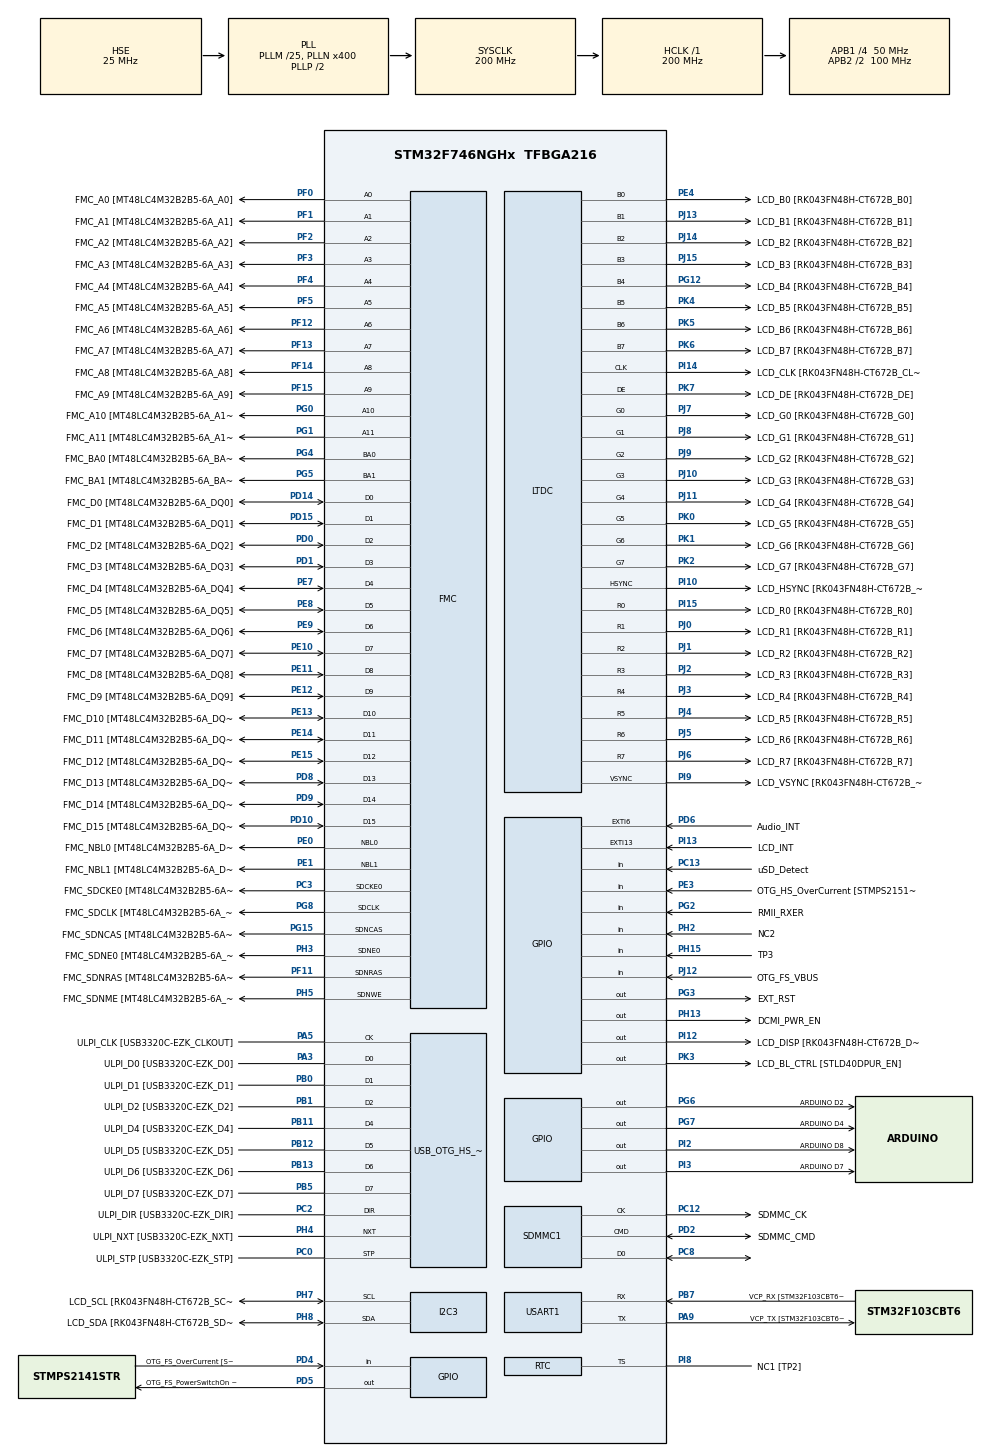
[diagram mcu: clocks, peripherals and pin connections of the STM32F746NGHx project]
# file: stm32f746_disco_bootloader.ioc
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PD12.GPIO_Label=QSPI_D1 [N25Q128A13EF840E_DQ1]
FMC.SDClockPeriod2=FMC_SDRAM_CLOCK_PERIOD_2
FATFS._USE_LFN=1
FMC.SDClockPeriod1=FMC_SDRAM_CLOCK_PERIOD_2
SH.FMC_A0.0=FMC_A0,12b-sda1
FATFS0.BSP.api=Unknown
PH15.GPIO_Label=TP3
NVIC.TIM6_DAC_IRQn=true\:0\:0\:false\:false\:true\:false\:true
PG8.Signal=FMC_SDCLK
PG0.Signal=FMC_A10
PI15.GPIO_Label=LCD_R0 [RK043FN48H-CT672B_R0]
PK1.Signal=LTDC_G6
SH.FMC_D5_DA5.0=FMC_D5,sd-16b-d1
PF10.GPIO_PuPd=GPIO_NOPULL
SH.FMC_D9_DA9.0=FMC_D9,sd-16b-d1
PG15.GPIO_Label=FMC_SDNCAS [MT48LC4M32B2B5-6A_CAS]
PF7.Signal=ADC3_IN5
NVIC.DMA2D_IRQn=true\:0\:0\:false\:false\:true\:true\:true
RCC.PLL48CLockSelection=RCC_CLK48SOURCE_PLLSAIP
SH.FMC_SDNWE.0=FMC_SDNWE,12b-sda1
PH9.Signal=DCMI_D0
SH.FMC_D11_DA11.0=FMC_D11,sd-16b-d1
PJ5.Mode=RGB888
RCC.APB2TimFreq_Value=200000000
PB6.Signal=QUADSPI_BK1_NCS
PC7.Signal=USART6_RX
PD0.Signal=FMC_D2_DA2
PD8.Signal=FMC_D13_DA13
PE1.Signal=FMC_NBL1
FATFS0.BSP.ip=GPIO
NVIC.TIM1_TRG_COM_TIM11_IRQn=true\:0\:0\:false\:false\:true\:true\:true
PF1.GPIO_Label=FMC_A1 [MT48LC4M32B2B5-6A_A1]
PI4.GPIO_Label=SAI2_MCLKA [WM8994ECS/R_MCLK1]
PK4.GPIO_Label=LCD_B5 [RK043FN48H-CT672B_B5]
PD1.GPIO_Label=FMC_D3 [MT48LC4M32B2B5-6A_DQ3]
PB12.GPIO_Label=ULPI_D5 [USB3320C-EZK_D5]
PJ14.Mode=RGB888
FMC.SelfRefreshTime1=4
PF12.GPIO_Label=FMC_A6 [MT48LC4M32B2B5-6A_A6]
LTDC.PixelFormat_L0=LTDC_PIXEL_FORMAT_RGB565
SH.S_TIM12_CH1.0=TIM12_CH1
PC4.GPIO_Label=RMII_RXD0 [LAN8742A-CZ-TR_RXD0]
PE9.Signal=FMC_D6_DA6
SH.FMC_A2.0=FMC_A2,12b-sda1
PB1.GPIO_Label=ULPI_D2 [USB3320C-EZK_D2]
PE4.GPIO_Label=LCD_B0 [RK043FN48H-CT672B_B0]
PG4.GPIO_Label=FMC_BA0 [MT48LC4M32B2B5-6A_BA0]
PA8.Signal=S_TIM1_CH1
SH.FMC_D1_DA1.0=FMC_D1,sd-16b-d1
LTDC.HSync=41
PJ14.Signal=LTDC_B2
PB9.Signal=I2C1_SDA
Mcu.Package=TFBGA216
PB1.Signal=USB_OTG_HS_ULPI_D2
PB14.GPIO_PuPd=GPIO_NOPULL
NVIC.TimeBase=TIM6_DAC_IRQn
PD12.Signal=QUADSPI_BK1_IO1
NVIC.TimeBaseIP=TIM6
PB9.GPIO_PuPd=GPIO_NOPULL
PA10.Signal=USB_OTG_FS_ID
VP_RTC_VS_RTC_Calendar.Mode=RTC_Calendar
PE12.GPIO_Label=FMC_D9 [MT48LC4M32B2B5-6A_DQ9]
FMC.WriteRecoveryTime1=3
RCC.APB2CLKDivider=RCC_HCLK_DIV2
LTDC.VSync=10
RCC.APB1TimFreq_Value=100000000
PC14/OSC32_IN.GPIO_Label=RCC_OSC32_IN
FMC.RowCycleDelay2=7
FMC.RowCycleDelay1=7
PB13.Mode=Host_HS
PJ13.Mode=RGB888
PH8.Mode=I2C
PF9.GPIO_PuPd=GPIO_NOPULL
PA4.GPIO_Label=DCMI_HSYNC
PA8.GPIO_Speed=GPIO_SPEED_FREQ_LOW
PD15.Signal=FMC_D1_DA1
PJ1.GPIO_Label=LCD_R2 [RK043FN48H-CT672B_R2]
PG12.Signal=LTDC_B4
PA5.Mode=Host_HS
FATFS0.BSP.STBoard=false
PK4.Signal=LTDC_B5
SH.FMC_A4.0=FMC_A4,12b-sda1
PH13.Signal=GPIO_Output
PI13.GPIO_ModeDefaultEXTI=GPIO_MODE_EVT_RISING
PG5.Signal=FMC_A15_BA1
PC13.Signal=GPIO_Input
SH.FMC_D10_DA10.0=FMC_D10,sd-16b-d1
FATFS0.BSP.mode=Input
PD3.Signal=DCMI_D5
PI10.Mode=RGB888
PC2.Signal=USB_OTG_HS_ULPI_DIR
PI12.Signal=GPIO_Output
TIM11.Prescaler=4999
PJ11.Signal=LTDC_G4
RCC.PLLSAIRDiv=RCC_PLLSAIDIVR_4
PF8.GPIO_Label=ARDUINO A3
LTDC.ImageWidth_L0=480
PD10.Signal=FMC_D15_DA15
PJ6.Mode=RGB888
PA3.Mode=Host_HS
PB8.GPIO_Label=ARDUINO SCL/D15
PJ8.GPIO_Label=LCD_G1 [RK043FN48H-CT672B_G1]
PJ3.Signal=LTDC_R4
PI8.GPIO_Label=NC1 [TP2]
PA8.GPIO_Label=ARDUINO PWM/D10
Dma.USART1_RX.0.Direction=DMA_PERIPH_TO_MEMORY
PE8.GPIO_Label=FMC_D5 [MT48LC4M32B2B5-6A_DQ5]
PH11.GPIO_Label=DCMI_D2
PJ11.GPIO_Label=LCD_G4 [RK043FN48H-CT672B_G4]
PB14.Signal=SPI2_MISO
PA5.Signal=USB_OTG_HS_ULPI_CK
PC12.Mode=SD_1_bit
PF10.GPIO_Mode=GPIO_MODE_ANALOG
PJ4.GPIO_Label=LCD_R5 [RK043FN48H-CT672B_R5]
PE1.GPIO_Label=FMC_NBL1 [MT48LC4M32B2B5-6A_DQM1]
PK7.GPIO_Label=LCD_DE [RK043FN48H-CT672B_DE]
PI7.Signal=SAI2_FS_A
FMC.ReadBurst1=FMC_SDRAM_RBURST_ENABLE
SH.FMC_A6.0=FMC_A6,12b-sda1
FMC.ReadBurst2=FMC_SDRAM_RBURST_ENABLE
PE14.Signal=FMC_D11_DA11
PB4.GPIO_Label=ARDUINO PWM/D3
PB15.GPIO_Label=ARDUINO MOSI/PWM/D11
PG7.GPIO_Label=ARDUINO D4
PI2.Signal=GPIO_Output
PF4.GPIO_Label=FMC_A4 [MT48LC4M32B2B5-6A_A4]
PA1.GPIO_Label=RMII_REF_CLK [LAN8742A-CZ-TR_REFCLK0]
PF13.Signal=FMC_A7
PA0/WKUP.GPIO_PuPd=GPIO_NOPULL
PJ15.GPIO_Label=LCD_B3 [RK043FN48H-CT672B_B3]
PC7.GPIO_Label=ARDUINO RX/D0
PC8.Mode=SD_1_bit
PJ15.Mode=RGB888
PA5.GPIO_Label=ULPI_CLK [USB3320C-EZK_CLKOUT]
PK4.Mode=RGB888
PC12.GPIO_Label=SDMMC_CK
PE5.GPIO_Label=DCMI_D6
PJ8.Signal=LTDC_G1
PJ0.GPIO_Label=LCD_R1 [RK043FN48H-CT672B_R1]
ProjectManager.HeapSize=0xF000
PB1.Mode=Host_HS
PH6.Signal=S_TIM12_CH1
NVIC.PriorityGroup=NVIC_PRIORITYGROUP_4
PF0.GPIO_Label=FMC_A0 [MT48LC4M32B2B5-6A_A0]
PI1.GPIO_Mode=GPIO_MODE_AF_PP
PE3.Signal=GPIO_Input
PJ4.Mode=RGB888
PC15/OSC32_OUT.Signal=RCC_OSC32_OUT
PF4.Signal=FMC_A4
PD2.Signal=SDMMC1_CMD
FATFS0.BSP.name=Detect_SDIO
PI1.GPIO_Label=ARDUINO SCK/D13
Mcu.Family=STM32F7
LTDC.BlendingFactor1_L0=LTDC_BLENDING_FACTOR1_PAxCA
PK3.Signal=GPIO_Output
SH.FMC_A8.0=FMC_A8,12b-sda1
PC15/OSC32_OUT.GPIO_Label=RCC_OSC32_OUT
PH14.Signal=DCMI_D4
PH10.Signal=DCMI_D1
SH.FMC_D14_DA14.0=FMC_D14,sd-16b-d1
PG2.Signal=GPIO_Input
PE11.GPIO_Label=FMC_D8 [MT48LC4M32B2B5-6A_DQ8]
PD0.GPIO_Label=FMC_D2 [MT48LC4M32B2B5-6A_DQ2]
PC14/OSC32_IN.Mode=LSE-External-Oscillator
SH.FMC_A14_BA0.0=FMC_BA0,FourSdramBanks1
SH.FMC_A11.0=FMC_A11,12b-sda1
PB13.GPIO_Label=ULPI_D6 [USB3320C-EZK_D6]
PG5.GPIO_Label=FMC_BA1 [MT48LC4M32B2B5-6A_BA1]
PB15.Signal=SPI2_MOSI
VP_RTC_VS_RTC_Alarm_B_Intern.Mode=Alarm B
PG15.Signal=FMC_SDNCAS
PG11.Signal=ETH_TX_EN
PJ5.GPIO_Label=LCD_R6 [RK043FN48H-CT672B_R6]
PJ14.GPIO_Label=LCD_B2 [RK043FN48H-CT672B_B2]
PD13.Signal=QUADSPI_BK1_IO3
PA15.GPIO_Label=ARDUINO PWM/D9
PJ2.Signal=LTDC_R3
SH.FMC_NBL1.0=FMC_NBL1,Sd2ByteEnable1
LTDC.WindowX1_L0=480
PI9.Mode=RGB888
PK2.Mode=RGB888
PA15.GPIO_ModeDefaultPP=GPIO_MODE_AF_PP
Dma.USART1_RX.0.Priority=DMA_PRIORITY_LOW
PA9.GPIO_Mode=GPIO_MODE_AF_PP
RCC.HSE_VALUE=25000000
FMC.ExitSelfRefreshDelay1=7
PF7.GPIO_Mode=GPIO_MODE_ANALOG
PI14.Mode=RGB888
PF8.GPIO_PuPd=GPIO_NOPULL
PA14.Mode=Serial_Wire
PH7.GPIO_Label=LCD_SCL [RK043FN48H-CT672B_SCL]
PJ7.GPIO_Label=LCD_G0 [RK043FN48H-CT672B_G0]
PF11.Signal=FMC_SDNRAS
PB5.Mode=Host_HS
PC11.GPIO_Label=SDMMC_D3
PJ12.GPIO_Label=OTG_FS_VBUS
PB7.Signal=USART1_RX
SH.S_TIM3_CH1.0=TIM3_CH1
Dma.USART1_RX.0.MemInc=DMA_MINC_ENABLE
PI8.Mode=Timestamp enabled - Input Enabled to TS
PB7.GPIO_Label=VCP_RX [STM32F103CBT6_PA2]
PD13.GPIO_Label=QSPI_D3 [N25Q128A13EF840E_DQ3]
PA6.Signal=DCMI_PIXCLK
PB12.Mode=Host_HS
PB15.GPIO_PuPd=GPIO_NOPULL
PD5.GPIO_Label=OTG_FS_PowerSwitchOn [STMPS2141STR_EN]
PA15.Signal=S_TIM2_CH1_ETR
PF8.Signal=ADC3_IN6
PG0.GPIO_Label=FMC_A10 [MT48LC4M32B2B5-6A_A10]
PI0.GPIO_Label=ARDUINO PWM/CS/D5
PA0/WKUP.GPIO_Mode=GPIO_MODE_ANALOG
Dma.USART1_RX.0.FIFOMode=DMA_FIFOMODE_DISABLE
FATFS._FS_LOCK=0
I2C3.Timing=0x00C0EAFF
PB5.GPIO_Label=ULPI_D7 [USB3320C-EZK_D7]
PG11.GPIO_Label=RMII_TX_EN [LAN8742A-CZ-TR_TXEN]
PD3.GPIO_Label=DCMI_D5
PC5.Signal=ETH_RXD1
PE7.Signal=FMC_D4_DA4
PD6.Signal=GPXTI6
Dma.Request0=USART1_RX
PF3.GPIO_Label=FMC_A3 [MT48LC4M32B2B5-6A_A3]
PI15.Mode=RGB888
PE2.GPIO_Label=QSPI_D2 [N25Q128A13EF840E_DQ2]
Dma.USART1_RX.0.Instance=DMA2_Stream2
PB4.Signal=S_TIM3_CH1
PG2.GPIO_Label=RMII_RXER
PA3.Signal=USB_OTG_HS_ULPI_D0
PK1.Mode=RGB888
PK6.Signal=LTDC_B7
NVIC.LTDC_IRQn=true\:0\:0\:false\:false\:true\:true\:true
PD15.GPIO_Label=FMC_D1 [MT48LC4M32B2B5-6A_DQ1]
LTDC.WindowY1_L0=272
PG7.Signal=GPIO_Output
PJ8.Mode=RGB888
PH12.GPIO_Label=DCMI_D3
PC11.Signal=SDMMC1_D3
PI14.Signal=LTDC_CLK
PC8.Signal=SDMMC1_D0
PC2.Mode=Host_HS
PE14.GPIO_Label=FMC_D11 [MT48LC4M32B2B5-6A_DQ11]
PD9.Signal=FMC_D14_DA14
PA9.GPIO_PuPd=GPIO_NOPULL
PA12.GPIO_Label=OTG_FS_P
PD8.GPIO_Label=FMC_D13 [MT48LC4M32B2B5-6A_DQ13]
FATFS0.BSP.instance=PC13
PG8.GPIO_Label=FMC_SDCLK [MT48LC4M32B2B5-6A_CLK]
USART1.VirtualMode-Asynchronous=VM_ASYNC
PA13.Signal=SYS_JTMS-SWDIO
PA9.Mode=Asynchronous
SH.S_TIM1_CH1.0=TIM1_CH1
PF6.Signal=ADC3_IN4
PB10.GPIO_Label=ULPI_D3 [USB3320C-EZK_D3]
SH.FMC_D13_DA13.0=FMC_D13,sd-16b-d1
PH8.Signal=I2C3_SDA
RCC.USBFreq_Value=48000000
PF9.GPIO_Label=ARDUINO A2
PD10.GPIO_Label=FMC_D15 [MT48LC4M32B2B5-6A_DQ15]
PA1.Signal=ETH_REF_CLK
PD2.Mode=SD_1_bit
PK5.Mode=RGB888
board=STM32F746G-DISCO
PG12.Mode=RGB888
RCC.VCOOutputFreq_Value=400000000
PI9.Signal=LTDC_VSYNC
PH4.GPIO_Label=ULPI_NXT [USB3320C-EZK_NXT]
PI13.GPIO_Label=LCD_INT
PI4.Signal=SAI2_MCLK_A
PC1.GPIO_Label=RMII_MDC [LAN8742A-CZ-TR_MDC]
SH.FMC_D12_DA12.0=FMC_D12,sd-16b-d1
PF15.GPIO_Label=FMC_A9 [MT48LC4M32B2B5-6A_A9]
PI1.GPIO_Speed=GPIO_SPEED_FREQ_LOW
PF1.Signal=FMC_A1
PF8.GPIO_Mode=GPIO_MODE_ANALOG
PJ0.Signal=LTDC_R1
PE0.Signal=FMC_NBL0
RTC.Alarm-Alarm\ A=RTC_ALARM_A
PE7.GPIO_Label=FMC_D4 [MT48LC4M32B2B5-6A_DQ4]
PE12.Signal=FMC_D9_DA9
FATFS._MAX_SS=4096
RCC.SYSCLKFreq_VALUE=200000000
PJ5.Signal=LTDC_R6
PA15.GPIO_Speed=GPIO_SPEED_FREQ_LOW
RCC.HSI_VALUE=16000000
PA8.GPIO_PuPd=GPIO_NOPULL
PH0/OSC_IN.GPIO_Label=OSC_25M [NZ2520SB-25.00M_OUT]
PF9.GPIO_Mode=GPIO_MODE_ANALOG
RCC.PLLQ=10
PI3.GPIO_Label=ARDUINO D7
PH3.Signal=FMC_SDNE0
RCC.PLLM=25
RCC.PLLN=400
PA9.GPIO_Speed=GPIO_SPEED_FREQ_LOW
PB8.GPIO_Speed=GPIO_SPEED_FREQ_LOW
PJ2.GPIO_Label=LCD_R3 [RK043FN48H-CT672B_R3]
VP_CRC_VS_CRC.Mode=CRC_Activate
LTDC.ImageHeight_L0=272
PB14.GPIO_Mode=GPIO_MODE_AF_PP
RCC.PLLI2SN=100
PB12.Signal=USB_OTG_HS_ULPI_D5
PJ13.Signal=LTDC_B1
PK1.GPIO_Label=LCD_G6 [RK043FN48H-CT672B_G6]
PA3.GPIO_Label=ULPI_D0 [USB3320C-EZK_D0]
PI12.PinState=GPIO_PIN_SET
SH.FMC_D7_DA7.0=FMC_D7,sd-16b-d1
RTC.Alarm_B-Alarm\ B=RTC_ALARM_B
PK5.Signal=LTDC_B6
PB15.GPIO_Mode=GPIO_MODE_AF_PP
VP_SYS_VS_tim6.Mode=TIM6
PJ9.Mode=RGB888
PH12.Signal=DCMI_D3
FMC.RCDDelay1=2
VP_FATFS_VS_SDIO.Mode=SDIO
PK0.Mode=RGB888
PG4.Signal=FMC_A14_BA0
PC12.Signal=SDMMC1_CK
PB14.GPIO_Label=ARDUINO MISO/D12
PA14.GPIO_Label=SWCLK
PG6.GPIO_Label=ARDUINO D2
PH6.GPIO_Label=ARDUINO PWM/D6
FMC.LoadToActiveDelay1=2
PK6.GPIO_Label=LCD_B7 [RK043FN48H-CT672B_B7]
PC6.GPIO_Label=ARDUINO TX/D1
VP_RTC_VS_RTC_Activate.Mode=RTC_Enabled
PI6.GPIO_Label=SAI2_SDA [WM8994ECS/R_DACDAT1]
PB6.GPIO_Label=QSPI_NCS [N25Q128A13EF840E_S]
PJ6.GPIO_Label=LCD_R7 [RK043FN48H-CT672B_R7]
PB13.Signal=USB_OTG_HS_ULPI_D6
PD6.GPIO_Label=Audio_INT
PG13.Signal=ETH_TXD0
PE6.GPIO_Label=DCMI_D7
PF6.GPIO_Label=ARDUINO A5
RCC.SYSCLKSource=RCC_SYSCLKSOURCE_PLLCLK
PJ10.Signal=LTDC_G3
SH.FMC_A15_BA1.0=FMC_BA1,FourSdramBanks1
PB7.GPIO_Mode=GPIO_MODE_AF_PP
PJ13.GPIO_Label=LCD_B1 [RK043FN48H-CT672B_B1]
PI0.GPIO_PuPd=GPIO_NOPULL
PH5.Signal=FMC_SDNWE
PD4.Signal=GPIO_Input
PH1/OSC_OUT.Signal=RCC_OSC_OUT
PC3.Signal=FMC_SDCKE0
PE5.Signal=DCMI_D6
PF10.GPIO_Label=ARDUINO A1
PH10.GPIO_Label=DCMI_D1
PB2.Signal=QUADSPI_CLK
FATFS0.BSP.i2caddr=0
PK7.Mode=RGB888
PJ2.Mode=RGB888
PI6.Signal=SAI2_SD_A
PI3.Signal=GPIO_Output
PE2.Signal=QUADSPI_BK1_IO2
PF3.Signal=FMC_A3
PE10.Signal=FMC_D7_DA7
FATFS._FS_TIMEOUT=10000
RCC.SDMMCClockSelection=RCC_SDMMC1CLKSOURCE_CLK48
PD6.GPIO_ModeDefaultEXTI=GPIO_MODE_EVT_RISING
FATFS0.BSP.solution=PC13
PJ4.Signal=LTDC_R5
SH.FMC_A1.0=FMC_A1,12b-sda1
PH2.Signal=GPIO_Input
NVIC.DMA2_Stream2_IRQn=true\:0\:0\:false\:false\:true\:false\:true
SH.FMC_SDCLK.0=FMC_SDCLK,12b-sda1
PF14.Signal=FMC_A8
VP_DMA2D_VS_DMA2D.Mode=DMA2D_Activate
PF6.GPIO_Mode=GPIO_MODE_ANALOG
PE10.GPIO_Label=FMC_D7 [MT48LC4M32B2B5-6A_DQ7]
PJ1.Mode=RGB888
SH.FMC_D3_DA3.0=FMC_D3,sd-16b-d1
FATFS._MIN_SS=512
PI10.GPIO_Label=LCD_HSYNC [RK043FN48H-CT672B_HSYNC]
PB7.GPIO_PuPd=GPIO_NOPULL
PK3.PinState=GPIO_PIN_SET
PH15.Signal=GPIO_Input
PD9.GPIO_Label=FMC_D14 [MT48LC4M32B2B5-6A_DQ14]
PG9.Signal=DCMI_VSYNC
PA9.GPIO_Label=VCP_TX [STM32F103CBT6_PA3]
PB8.GPIO_PuPd=GPIO_NOPULL
PC6.Signal=USART6_TX
PB11.GPIO_Label=ULPI_D4 [USB3320C-EZK_D4]
PD7.Signal=SPDIFRX_IN0
PD1.Signal=FMC_D3_DA3
PA11.GPIO_Label=OTG_FS_N
PF14.GPIO_Label=FMC_A8 [MT48LC4M32B2B5-6A_A8]
PC0.Signal=USB_OTG_HS_ULPI_STP
RCC.APB1CLKDivider=RCC_HCLK_DIV4
PF13.GPIO_Label=FMC_A7 [MT48LC4M32B2B5-6A_A7]
PG13.GPIO_Label=RMII_TXD0 [LAN8742A-CZ-TR_TXD0]
PG10.Signal=SAI2_SD_B
SH.FMC_A3.0=FMC_A3,12b-sda1
PJ7.Signal=LTDC_G0
FMC.CASLatency1=FMC_SDRAM_CAS_LATENCY_3
PB11.Mode=Host_HS
PI0.GPIO_Speed=GPIO_SPEED_FREQ_LOW
PB14.GPIO_Speed=GPIO_SPEED_FREQ_LOW
SH.FMC_D15_DA15.0=FMC_D15,sd-16b-d1
PA9.Signal=USART1_TX
PB4.GPIO_PuPd=GPIO_NOPULL
PE9.GPIO_Label=FMC_D6 [MT48LC4M32B2B5-6A_DQ6]
Dma.USART1_RX.0.PeriphInc=DMA_PINC_DISABLE
PB10.Signal=USB_OTG_HS_ULPI_D3
FATFS.BSP.number=1
PJ15.Signal=LTDC_B3
PH9.GPIO_Label=DCMI_D0
PI9.GPIO_Label=LCD_VSYNC [RK043FN48H-CT672B_VSYNC]
PA8.GPIO_ModeDefaultPP=GPIO_MODE_AF_PP
PE15.Signal=FMC_D12_DA12
PE8.Signal=FMC_D5_DA5
PI1.Signal=SPI2_SCK
FATFS0.BSP.i2creg=0
PA0/WKUP.GPIO_Label=ARDUINO A0
PG14.GPIO_Label=RMII_TXD1 [LAN8742A-CZ-TR_TXD1]
PA13.Mode=Serial_Wire
SH.FMC_SDNCAS.0=FMC_SDNCAS,12b-sda1
PH4.Mode=Host_HS
PF7.GPIO_PuPd=GPIO_NOPULL
PH14.GPIO_Label=DCMI_D4
PA4.Signal=DCMI_HSYNC
PB5.Signal=USB_OTG_HS_ULPI_D7
PE13.GPIO_Label=FMC_D10 [MT48LC4M32B2B5-6A_DQ10]
PD11.Signal=QUADSPI_BK1_IO0
SH.FMC_A5.0=FMC_A5,12b-sda1
LTDC.Alpha_L0=255
PA11.Signal=USB_OTG_FS_DM
SH.S_TIM2_CH1_ETR.0=TIM2_CH1
PK3.GPIO_Label=LCD_BL_CTRL [STLD40DPUR_EN]
PF9.Signal=ADC3_IN7
PJ10.Mode=RGB888
PF6.GPIO_PuPd=GPIO_NOPULL
PC3.GPIO_Label=FMC_SDCKE0 [MT48LC4M32B2B5-6A_CKE]
PG3.GPIO_Label=EXT_RST
PB0.Signal=USB_OTG_HS_ULPI_D1
PC1.Signal=ETH_MDC
PG10.GPIO_Label=SAI2_SDB [WM8994ECS/R_ADCDAT1]
PD2.GPIO_Label=SDMMC_CMD
PH2.GPIO_Label=NC2
PC3.Mode=SdramChipSelect1_1
PK7.Signal=LTDC_DE
RCC.CortexFreq_Value=200000000
PG6.Signal=GPIO_Output
LTDC.HBP=13
PC10.Signal=SDMMC1_D2
SH.FMC_NBL0.0=FMC_NBL0,Sd2ByteEnable1
PC0.GPIO_Label=ULPI_STP [USB3320C-EZK_STP]
SH.FMC_D6_DA6.0=FMC_D6,sd-16b-d1
SDMMC1.ClockDiv=4
PA0/WKUP.Signal=ADCx_IN0
PB0.GPIO_Label=ULPI_D1 [USB3320C-EZK_D1]
PH5.GPIO_Label=FMC_SDNME [MT48LC4M32B2B5-6A_WE]
PI5.GPIO_Label=SAI2_SCKA [WM8994ECS/R_BCLK1]
PC13.GPIO_Label=uSD_Detect
PK5.GPIO_Label=LCD_B6 [RK043FN48H-CT672B_B6]
PB11.Signal=USB_OTG_HS_ULPI_D4
PI14.GPIO_Label=LCD_CLK [RK043FN48H-CT672B_CLK]
VP_RTC_VS_RTC_Alarm_A_Intern.Mode=Alarm A
ProjectManager.StackSize=0xF000
PH3.Mode=SdramChipSelect1_1
PJ6.Signal=LTDC_R7
SH.FMC_A7.0=FMC_A7,12b-sda1
PA12.Signal=USB_OTG_FS_DP
PH0/OSC_IN.Mode=HSE-External-Oscillator
PD11.GPIO_Label=QSPI_D0 [N25Q128A13EF840E_DQ0]
RCC.HCLKFreq_Value=200000000
PF11.GPIO_Label=FMC_SDNRAS [MT48LC4M32B2B5-6A_RAS]
PF12.Signal=FMC_A6
PI13.Signal=GPXTI13
SH.FMC_A10.0=FMC_A10,12b-sda1
RCC.AHBFreq_Value=200000000
SH.FMC_D8_DA8.0=FMC_D8,sd-16b-d1
FMC.RPDelay2=2
FMC.RPDelay1=2
PI8.Signal=RTC_TS
SH.FMC_D2_DA2.0=FMC_D2,sd-16b-d1
NVIC.I2C3_EV_IRQn=true\:0\:0\:false\:false\:true\:true\:true
PE13.Signal=FMC_D10_DA10
PF7.GPIO_Label=ARDUINO A4
PI1.GPIO_PuPd=GPIO_NOPULL
PI5.Signal=SAI2_SCK_A
PK6.Mode=RGB888
PI0.Signal=S_TIM5_CH4
PA10.GPIO_Label=OTG_FS_ID
LTDC.HFP=32
LTDC.BlendingFactor2_L0=LTDC_BLENDING_FACTOR2_PAxCA
SH.ADCx_IN0.0=ADC3_IN0
FMC.ReadPipeDelay1=FMC_SDRAM_RPIPE_DELAY_1
FMC.ReadPipeDelay2=FMC_SDRAM_RPIPE_DELAY_1
PE4.Mode=RGB888
SH.FMC_SDNRAS.0=FMC_SDNRAS,12b-sda1
DMA2D.ColorMode=DMA2D_OUTPUT_RGB565
LTDC.ActiveW=480
PE4.Signal=LTDC_B0
PH1/OSC_OUT.Mode=HSE-External-Oscillator
PD7.GPIO_Label=SPDIF_RX0 [74LVC1G04SE_4]
PH7.Mode=I2C
PJ0.Mode=RGB888
PJ9.Signal=LTDC_G2
SH.FMC_D0_DA0.0=FMC_D0,sd-16b-d1
PJ12.Signal=GPIO_Input
PC14/OSC32_IN.Signal=RCC_OSC32_IN
PK0.GPIO_Label=LCD_G5 [RK043FN48H-CT672B_G5]
PA2.GPIO_Label=RMII_MDIO [LAN8742A-CZ-TR_MDIO]
PF5.GPIO_Label=FMC_A5 [MT48LC4M32B2B5-6A_A5]
SH.FMC_A9.0=FMC_A9,12b-sda1
PJ1.Signal=LTDC_R2
SH.FMC_D4_DA4.0=FMC_D4,sd-16b-d1
PI12.GPIO_Label=LCD_DISP [RK043FN48H-CT672B_DISP] 
PE0.GPIO_Label=FMC_NBL0 [MT48LC4M32B2B5-6A_DQM0]
PH3.GPIO_Label=FMC_SDNE0 [MT48LC4M32B2B5-6A_CS]
PF5.Signal=FMC_A5
RCC.PLLSAIP=RCC_PLLSAIP_DIV4
RCC.PLLSAIR=5
PH7.Signal=I2C3_SCL
PB9.GPIO_Speed=GPIO_SPEED_FREQ_LOW
PJ3.GPIO_Label=LCD_R4 [RK043FN48H-CT672B_R4]
PK2.GPIO_Label=LCD_G7 [RK043FN48H-CT672B_G7]
Dma.USART1_RX.0.Mode=DMA_CIRCULAR
PJ7.Mode=RGB888
PF0.Signal=FMC_A0
PI2.GPIO_Label=ARDUINO D8
PC2.GPIO_Label=ULPI_DIR [USB3320C-EZK_DIR]
PB7.GPIO_Speed=GPIO_SPEED_FREQ_LOW
PB3.GPIO_Label=SWO
RCC.PLLSourceVirtual=RCC_PLLSOURCE_HSE
PK2.Signal=LTDC_G7
LTDC.FBStartAdress_L0=0xC0000000
Dma.USART1_RX.0.PeriphDataAlignment=DMA_PDATAALIGN_BYTE
PB9.GPIO_Label=ARDUINO SDA/D14
PC10.GPIO_Label=SDMMC_D2
PH11.Signal=DCMI_D2
PG3.Signal=GPIO_Output
PG1.Signal=FMC_A11
PC4.Signal=ETH_RXD0
PI0.GPIO_ModeDefaultPP=GPIO_MODE_AF_PP
PI10.Signal=LTDC_HSYNC
PD5.Signal=GPIO_Output
VP_RNG_VS_RNG.Mode=RNG_Activate
VP_TIM11_VS_ClockSourceINT.Mode=Enable_Timer
PC0.Mode=Host_HS
PJ11.Mode=RGB888
PH13.GPIO_Label=DCMI_PWR_EN
PH8.GPIO_Label=LCD_SDA [RK043FN48H-CT672B_SDA]
PE15.GPIO_Label=FMC_D12 [MT48LC4M32B2B5-6A_DQ12]
PH4.Signal=USB_OTG_HS_ULPI_NXT
ProjectManager.TargetToolchain=STM32CubeIDE
LTDC.ActiveH=272
PJ9.GPIO_Label=LCD_G2 [RK043FN48H-CT672B_G2]
PF2.Signal=FMC_A2
PE11.Signal=FMC_D8_DA8
PK0.Signal=LTDC_G5
PG9.GPIO_Label=DCMI_VSYNC
PG14.Signal=ETH_TXD1
PB4.GPIO_ModeDefaultPP=GPIO_MODE_AF_PP
PJ10.GPIO_Label=LCD_G3 [RK043FN48H-CT672B_G3]
PB0.Mode=Host_HS
PG1.GPIO_Label=FMC_A11 [MT48LC4M32B2B5-6A_A11]
TIM11.Period=999
PB9.GPIO_Mode=GPIO_MODE_AF_OD
PJ3.Mode=RGB888
PH0/OSC_IN.Signal=RCC_OSC_IN
PB4.GPIO_Speed=GPIO_SPEED_FREQ_LOW
RCC.APB2Freq_Value=100000000
LTDC.Layers=0
PD4.GPIO_Label=OTG_FS_OverCurrent [STMPS2141STR_Fault]
PF10.Signal=ADC3_IN8
PB15.GPIO_Speed=GPIO_SPEED_FREQ_LOW
Dma.USART1_RX.0.MemDataAlignment=DMA_MDATAALIGN_BYTE
PI7.GPIO_Label=SAI2_FSA [WM8994ECS/R_LRCLK1]
SH.S_TIM5_CH4.0=TIM5_CH4
PF15.Signal=FMC_A9
PD14.GPIO_Label=FMC_D0 [MT48LC4M32B2B5-6A_DQ0]
PD5.PinState=GPIO_PIN_SET
PE6.Signal=DCMI_D7
Mcu.Name=STM32F746NGHx
PA13.GPIO_Label=SWDIO
PA2.Signal=ETH_MDIO
PD14.Signal=FMC_D0_DA0
PB3.Signal=SYS_JTDO-SWO
PA7.GPIO_Label=RMII_CRS_DV [LAN8742A-CZ-TR_CRS_DV]
PC5.GPIO_Label=RMII_RXD1 [LAN8742A-CZ-TR_RXD1]
PC15/OSC32_OUT.Mode=LSE-External-Oscillator
PB7.Mode=Asynchronous
PA14.Signal=SYS_JTCK-SWCLK
PG12.GPIO_Label=LCD_B4 [RK043FN48H-CT672B_B4]
PK3.GPIO_Speed=GPIO_SPEED_FREQ_LOW
PA15.GPIO_PuPd=GPIO_NOPULL
PI15.Signal=LTDC_R0
PB8.Signal=I2C1_SCL
PE3.GPIO_Label=OTG_HS_OverCurrent [STMPS2151STR_FAULT]
PC9.Signal=SDMMC1_D1
PB8.GPIO_Mode=GPIO_MODE_AF_OD
RCC.APB1Freq_Value=50000000
PA7.Signal=ETH_CRS_DV
PF2.GPIO_Label=FMC_A2 [MT48LC4M32B2B5-6A_A2]

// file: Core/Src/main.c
/* USER CODE BEGIN Header */
/**
  ******************************************************************************
  * @file           : main.c
  * @brief          : Main program body
  ******************************************************************************
  * @attention
  *
  * <h2><center>&copy; Copyright (c) 2022 STMicroelectronics.
  * All rights reserved.</center></h2>
  *
  * This software component is licensed by ST under Ultimate Liberty license
  * SLA0044, the "License"; You may not use this file except in compliance with
  * the License. You may obtain a copy of the License at:
  *                             www.st.com/SLA0044
  *
  ******************************************************************************
  */
/* USER CODE END Header */
#include "main.h"
#include "crc.h"
#include "dma.h"
#include "dma2d.h"
#include "fatfs.h"
#include "i2c.h"
#include "ltdc.h"
#include "rng.h"
#include "rtc.h"
#include "sdmmc.h"
#include "tim.h"
#include "usart.h"
#include "gpio.h"
#include "fmc.h"

/* USER CODE BEGIN Includes */
#include "./bootloader/bootloader.h"
/* USER CODE END Includes */

void SystemClock_Config(void);

/* USER CODE BEGIN 0 */

/*
 *	Using printf at uart1
 */
int __io_putchar(int ch)
{
	HAL_UART_Transmit(&huart1, (uint8_t *)&ch, 1, 0xFFFF);
	return ch;
}

/* USER CODE END 0 */

int main(void)
{

  /* MCU Configuration--------------------------------------------------------*/

  /* Reset of all peripherals, Initializes the Flash interface and the Systick. */
  HAL_Init();

  /* Configure the system clock */
  SystemClock_Config();

  /* Initialize all configured peripherals */
  MX_GPIO_Init();
  MX_DMA_Init();
  MX_CRC_Init();
  MX_DMA2D_Init();
  MX_FMC_Init();
  MX_LTDC_Init();
  MX_RTC_Init();
  MX_SDMMC1_SD_Init();
  MX_USART1_UART_Init();
  MX_RNG_Init();
  MX_I2C3_Init();
  MX_TIM11_Init();
  MX_FATFS_Init();
  /* USER CODE BEGIN 2 */
  //__HAL_UART_ENABLE_IT(&huart1,UART_IT_RXNE);
  bootloader_application();
  /* USER CODE END 2 */

  /* Infinite loop */
  while (1)
  {

  }
}

void SystemClock_Config(void)
{
  RCC_OscInitTypeDef RCC_OscInitStruct = {0};
  RCC_ClkInitTypeDef RCC_ClkInitStruct = {0};
  RCC_PeriphCLKInitTypeDef PeriphClkInitStruct = {0};

  /** Configure LSE Drive Capability
  */
  HAL_PWR_EnableBkUpAccess();
  /** Configure the main internal regulator output voltage
  */
  __HAL_RCC_PWR_CLK_ENABLE();
  __HAL_PWR_VOLTAGESCALING_CONFIG(PWR_REGULATOR_VOLTAGE_SCALE1);
  /** Initializes the RCC Oscillators according to the specified parameters
  * in the RCC_OscInitTypeDef structure.
  */
  RCC_OscInitStruct.OscillatorType = RCC_OSCILLATORTYPE_LSI|RCC_OSCILLATORTYPE_HSE;
  RCC_OscInitStruct.HSEState = RCC_HSE_ON;
  RCC_OscInitStruct.LSIState = RCC_LSI_ON;
  RCC_OscInitStruct.PLL.PLLState = RCC_PLL_ON;
  RCC_OscInitStruct.PLL.PLLSource = RCC_PLLSOURCE_HSE;
  RCC_OscInitStruct.PLL.PLLM = 25;
  RCC_OscInitStruct.PLL.PLLN = 400;
  RCC_OscInitStruct.PLL.PLLP = RCC_PLLP_DIV2;
  RCC_OscInitStruct.PLL.PLLQ = 10;
  if (HAL_RCC_OscConfig(&RCC_OscInitStruct) != HAL_OK)
  {
    Error_Handler();
  }
  /** Activate the Over-Drive mode
  */
  if (HAL_PWREx_EnableOverDrive() != HAL_OK)
  {
    Error_Handler();
  }
  /** Initializes the CPU, AHB and APB buses clocks
  */
  RCC_ClkInitStruct.ClockType = RCC_CLOCKTYPE_HCLK|RCC_CLOCKTYPE_SYSCLK
                              |RCC_CLOCKTYPE_PCLK1|RCC_CLOCKTYPE_PCLK2;
  RCC_ClkInitStruct.SYSCLKSource = RCC_SYSCLKSOURCE_PLLCLK;
  RCC_ClkInitStruct.AHBCLKDivider = RCC_SYSCLK_DIV1;
  RCC_ClkInitStruct.APB1CLKDivider = RCC_HCLK_DIV4;
  RCC_ClkInitStruct.APB2CLKDivider = RCC_HCLK_DIV2;

  if (HAL_RCC_ClockConfig(&RCC_ClkInitStruct, FLASH_LATENCY_6) != HAL_OK)
  {
    Error_Handler();
  }
  PeriphClkInitStruct.PeriphClockSelection = RCC_PERIPHCLK_LTDC|RCC_PERIPHCLK_RTC
                              |RCC_PERIPHCLK_USART1|RCC_PERIPHCLK_I2C3
                              |RCC_PERIPHCLK_SDMMC1|RCC_PERIPHCLK_CLK48;
  PeriphClkInitStruct.PLLSAI.PLLSAIN = 192;
  PeriphClkInitStruct.PLLSAI.PLLSAIR = 5;
  PeriphClkInitStruct.PLLSAI.PLLSAIQ = 2;
  PeriphClkInitStruct.PLLSAI.PLLSAIP = RCC_PLLSAIP_DIV4;
  PeriphClkInitStruct.PLLSAIDivQ = 1;
  PeriphClkInitStruct.PLLSAIDivR = RCC_PLLSAIDIVR_4;
  PeriphClkInitStruct.RTCClockSelection = RCC_RTCCLKSOURCE_LSI;
  PeriphClkInitStruct.Usart1ClockSelection = RCC_USART1CLKSOURCE_PCLK2;
  PeriphClkInitStruct.I2c3ClockSelection = RCC_I2C3CLKSOURCE_PCLK1;
  PeriphClkInitStruct.Clk48ClockSelection = RCC_CLK48SOURCE_PLLSAIP;
  PeriphClkInitStruct.Sdmmc1ClockSelection = RCC_SDMMC1CLKSOURCE_CLK48;
  if (HAL_RCCEx_PeriphCLKConfig(&PeriphClkInitStruct) != HAL_OK)
  {
    Error_Handler();
  }
}

 /**
  * @brief  Period elapsed callback in non blocking mode
  * @note   This function is called  when TIM6 interrupt took place, inside
  * HAL_TIM_IRQHandler(). It makes a direct call to HAL_IncTick() to increment
  * a global variable "uwTick" used as application time base.
  * @param  htim : TIM handle
  * @retval None
  */
void HAL_TIM_PeriodElapsedCallback(TIM_HandleTypeDef *htim)
{
  if (htim->Instance == TIM6) {
    HAL_IncTick();
  }
}

void Error_Handler(void)
{
  __disable_irq();
  while (1)
  {
  }
}

/************************ (C) COPYRIGHT STMicroelectronics *****END OF FILE****/
